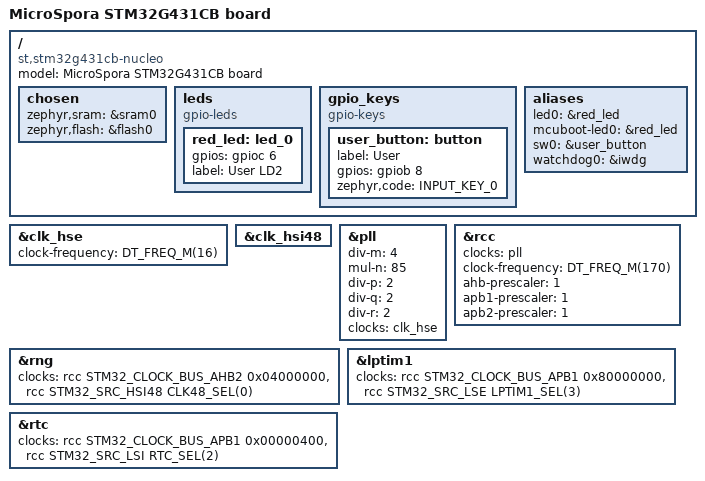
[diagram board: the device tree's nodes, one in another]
/*
 * Copyright (c) 2019 Richard Osterloh <richard.osterloh@gmail.com>
 *
 * SPDX-License-Identifier: Apache-2.0
 */

/dts-v1/;
#include <st/g4/stm32g431Xb.dtsi>
#include <st/g4/stm32g431r(6-8-b)tx-pinctrl.dtsi>
#include <zephyr/dt-bindings/input/input-event-codes.h>

/ {
	model = "MicroSpora STM32G431CB board";
	compatible = "st,stm32g431cb-nucleo";

	chosen {
		zephyr,sram = &sram0;
		zephyr,flash = &flash0;
	};

	leds: leds {
		compatible = "gpio-leds";

		red_led: led_0 {
			gpios = <&gpioc 6 GPIO_ACTIVE_HIGH>;
			label = "User LD2";
		};
	};

	gpio_keys {
		compatible = "gpio-keys";

		user_button: button {
			label = "User";
			gpios = <&gpiob 8 GPIO_ACTIVE_HIGH>;
			zephyr,code = <INPUT_KEY_0>;
		};
	};

	aliases {
		led0 = &red_led;
		mcuboot-led0 = &red_led;
		sw0 = &user_button;
		watchdog0 = &iwdg;
	};
};

&clk_hse {
	clock-frequency = <DT_FREQ_M(16)>;
	status = "okay";
};

&clk_hsi48 {
	status = "okay";
};

&pll {
	div-m = <4>;
	mul-n = <85>;
	div-p = <2>;
	div-q = <2>;
	div-r = <2>;
	clocks = <&clk_hse>;
	status = "okay";
};

&rcc {
	clocks = <&pll>;
	clock-frequency = <DT_FREQ_M(170)>;
	ahb-prescaler = <1>;
	apb1-prescaler = <1>;
	apb2-prescaler = <1>;
};

&rng {
	clocks = <&rcc STM32_CLOCK_BUS_AHB2 0x04000000>,
		 <&rcc STM32_SRC_HSI48 CLK48_SEL(0)>;
	status = "okay";
};


stm32_lp_tick_source: &lptim1 {
	clocks = <&rcc STM32_CLOCK_BUS_APB1 0x80000000>,
		 <&rcc STM32_SRC_LSE LPTIM1_SEL(3)>;
	status = "okay";
};

&rtc {
	clocks = <&rcc STM32_CLOCK_BUS_APB1 0x00000400>,
		 <&rcc STM32_SRC_LSI RTC_SEL(2)>;
	status = "okay";
};

